# RA register map
Vendor: Renesas; Series: All Chips; File version: x.xx
Registers are 32-bit, read-write, reset 0x0 unless marked. A register's access mark holds for its fields unless they carry their own. Offsets are from the block's base; [hi:lo] are bit positions; lines under a group give offsets from that group; {n}, {i} and the like mark numbered series; 'fields as' and 'values as' point back to an identical list.

## R_PORT0 — I/O Ports
Base 0x40040000
Same registers: R_PORT{n} {0x40040000+0x20*n} (n=1..11)
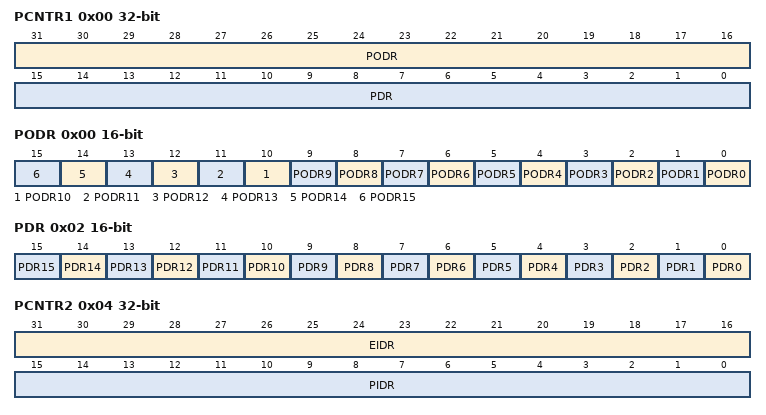
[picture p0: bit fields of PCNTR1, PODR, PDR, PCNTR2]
0x00 PCNTR1 — Port Control Register 1
  [31:16] PODR — Pmn Output Data
    0=Low output; 1=High output
  [15:0] PDR — Pmn Direction
    0=Input (functions as an input pin); 1=Output (functions as an output pin)
0x00 PODR 16-bit (alternate view of PCNTR1) — Output data register
  [n] PODR{n} (n=0..15) — Pmn Output Data
    0=Low output; 1=High output
0x02 PDR 16-bit (alternate view of PCNTR1) — Data direction register
  [n] PDR{n} (n=0..15) — Pmn Direction
    values as PCNTR1.PDR
0x04 PCNTR2 ro (reset mask 0xFFFF0000) — Port Control Register 2
  [31:16] EIDR — Pmn Event Input Data
    0=Low input; 1=High input
  [15:0] PIDR — Pmn Input Data
    0=Low input; 1=High input
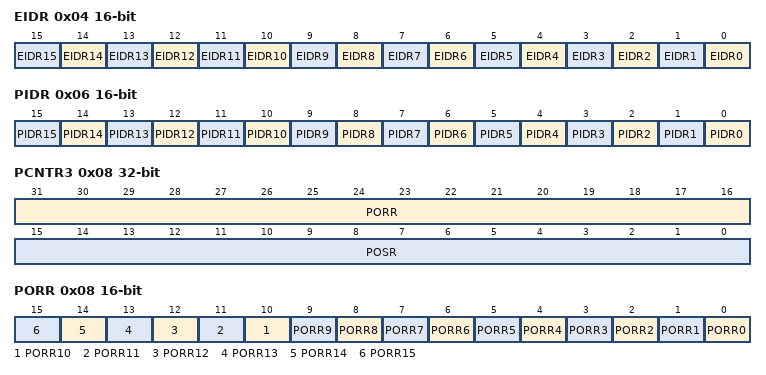
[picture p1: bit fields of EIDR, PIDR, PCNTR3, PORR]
0x04 EIDR 16-bit ro (alternate view of PCNTR2) — Event input data register
  [n] EIDR{n} (n=0..15) — Pmn Event Input Data
    0=Low input; 1=High input
0x06 PIDR 16-bit ro reset not defined (alternate view of PCNTR2) — Input data register
  [n] PIDR{n} (n=0..15) — Pmn Input Data
    0=Low input; 1=High input
0x08 PCNTR3 wo — Port Control Register 3
  [31:16] PORR — Pmn Output Reset
    0=No affect to output; 1=Low output
  [15:0] POSR — Pmn Output Set
    0=No affect to output; 1=High output
0x08 PORR 16-bit wo (alternate view of PCNTR3) — Output set register
  [n] PORR{n} (n=0..15) — Pmn Output Reset
    0=No affect to output; 1=Low output
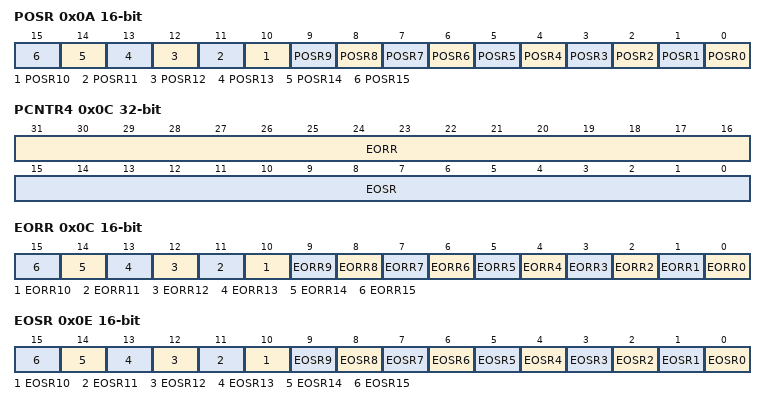
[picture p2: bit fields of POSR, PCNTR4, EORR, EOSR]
0x0A POSR 16-bit wo (alternate view of PCNTR3) — Output reset register
  [n] POSR{n} (n=0..15) — Pmn Output Set
    0=No affect to output; 1=High output
0x0C PCNTR4 — Port Control Register 4
  [31:16] EORR — Pmn Event Output Reset
    0=No affect to output; 1=Low output
  [15:0] EOSR — Pmn Event Output Set
    0=No affect to output; 1=High output
0x0C EORR 16-bit (alternate view of PCNTR4) — Event output set register
  [n] EORR{n} (n=0..15) — Pmn Event Output Reset
    0=No affect to output; 1=Low output
0x0E EOSR 16-bit (alternate view of PCNTR4) — Event output reset register
  [n] EOSR{n} (n=0..15) — Pmn Event Output Set
    0=No affect to output; 1=High output

## R_PFS — I/O Ports-PFS
Base 0x40040800
? PORT[{i}] (i=0..11; step 0x40) group — Port {i}
  {0x0+4j} PIN[{j}] (j=0..15) group — Pin Function Selects
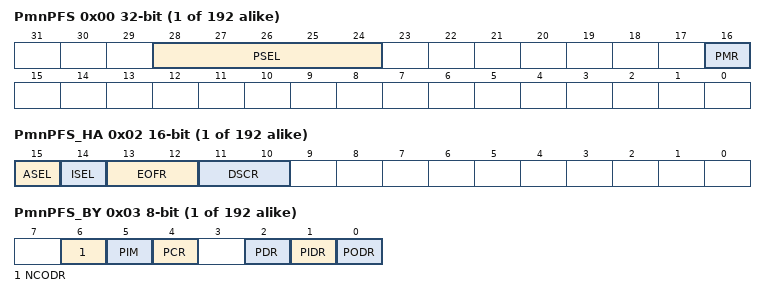
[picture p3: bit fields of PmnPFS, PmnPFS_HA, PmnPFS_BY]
    0x00 PmnPFS — Pin Function Control Register
      [28:24] PSEL — Port Function SelectThese bits select the peripheral function. For individual pin functions, see the MPC table
      [16] PMR — Port Mode Control
        0=Uses the pin as a general I/O pin; 1=Uses the pin as an I/O port for peripheral functions
    0x02 PmnPFS_HA 16-bit — Pin Function Control Register
      [15] ASEL — Analog Input enable
        0=Used other than as analog pin; 1=Used as analog pin
      [14] ISEL — IRQ input enable
        0=Not used as IRQn input pin; 1=Used as IRQn input pin
      [13:12] EOFR — Event on Falling/Rising
        0=Do not care; 1=Detect rising edge; 2=Detect falling edge; 3=Detect rising and falling edge
      [11:10] DSCR — Drive Strength Control Register
        0=Normal drive output; 1=Middle drive output; 2=Middle drive with IIC; 3=High-drive output
    0x03 PmnPFS_BY 8-bit (reset mask 0xFD) — Pin Function Control Register
      [6] NCODR — N-Channel Open Drain Control
        0=CMOS output; 1=NMOS open-drain output
      [5] PIM — Port Input Mode Control
        0=CMOS input; 1=TTL input
      [4] PCR — Pull-up Control
        0=Disables an input pull-up; 1=Enables an input pull-up
      [2] PDR — Port Direction
        0=Input (Functions as an input pin.); 1=Output (Functions as an output pin.)
      [1] PIDR ro — Port Input Data
        0=Low input; 1=High input
      [0] PODR — Port Output Data
        0=Low output; 1=High output
